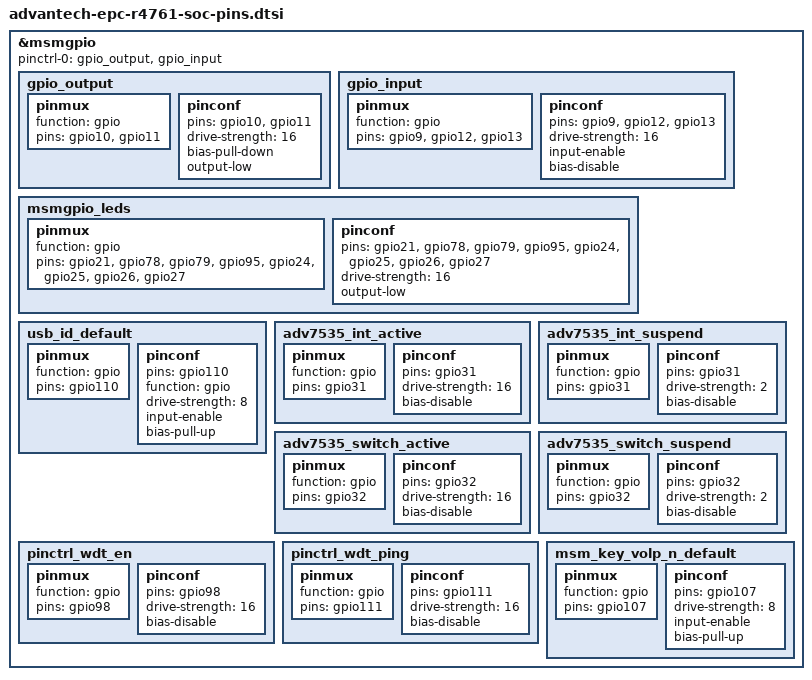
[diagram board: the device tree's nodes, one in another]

#include <dt-bindings/gpio/gpio.h>

&msmgpio {

	pinctrl-names = "default";
	pinctrl-0 = <&gpio_output &gpio_input>;

	gpio_output: gpio_output {
		pinmux {
			function = "gpio";
			pins = "gpio10", "gpio11";
		};
		pinconf {
			pins = "gpio10", "gpio11";
			drive-strength = <16>;
			bias-pull-down;
			output-low;
		};
	};

	gpio_input: gpio_input {
		pinmux {
			function = "gpio";
			pins = "gpio9", "gpio12", "gpio13";
		};
		pinconf {
			pins = "gpio9", "gpio12", "gpio13";
			drive-strength = <16>;
			input-enable;
			bias-disable;
		};
	};

	msmgpio_leds: msmgpio_leds {
		pinmux {
			function = "gpio";
			pins = "gpio21", "gpio78", "gpio79", "gpio95",
				"gpio24", "gpio25", "gpio26", "gpio27";
		};
		pinconf {
			pins = "gpio21", "gpio78", "gpio79", "gpio95",
				"gpio24", "gpio25", "gpio26", "gpio27";
			drive-strength = <16>;
			output-low;
		};
	};

	usb_id_default: usb_id_default {
		pinmux {
			function = "gpio";
			pins = "gpio110";
		};

		pinconf {
			pins = "gpio110";
			function = "gpio";
			drive-strength = <8>;
			input-enable;
			bias-pull-up;
		};
	};

	adv7535_int_active: adv7535_int_active {
		pinmux {
			function = "gpio";
			pins = "gpio31";
		};
		pinconf {
			pins = "gpio31";
			drive-strength = <16>;
			bias-disable;
		};
	};

	adv7535_int_suspend: adv7535_int_suspend {
		pinmux {
			function = "gpio";
			pins = "gpio31";
		};
		pinconf {
			pins = "gpio31";
			drive-strength = <2>;
			bias-disable;
		};
	};

	adv7535_switch_active: adv7535_switch_active {
		pinmux {
			function = "gpio";
			pins = "gpio32";
		};
		pinconf {
			pins = "gpio32";
			drive-strength = <16>;
			bias-disable;
		};
	};

	adv7535_switch_suspend: adv7535_switch_suspend {
		pinmux {
			function = "gpio";
			pins = "gpio32";
		};
		pinconf {
			pins = "gpio32";
			drive-strength = <2>;
			bias-disable;
		};
	};

	pinctrl_wdt_en: pinctrl_wdt_en {
		pinmux {
			function = "gpio";
			pins = "gpio98";
		};
		pinconf {
			pins = "gpio98";
			drive-strength = <16>;
			bias-disable;
		};
	};

	pinctrl_wdt_ping: pinctrl_wdt_ping  {
		pinmux {
			function = "gpio";
			pins = "gpio111";
		};
		pinconf {
			pins = "gpio111";
			drive-strength = <16>;
			bias-disable;
		};
	};

	msm_key_volp_n_default: msm_key_volp_n_default {
		pinmux {
			function = "gpio";
			pins = "gpio107";
		};
		pinconf {
			pins = "gpio107";
			drive-strength = <8>;
			input-enable;
			bias-pull-up;
		};
	};
};
